# CM41x_M4 register map
Vendor: Analog Devices; Series: CM41x_M4; File version: 1p0
CPU: CM4 r0p1, little endian, MPU, FPU, 4 interrupt priority bits
Registers are 32-bit, read-write, reset 0x0 unless marked. A register's access mark holds for its fields unless they carry their own. Offsets are from the block's base; [hi:lo] are bit positions; lines under a group give offsets from that group; {n}, {i} and the like mark numbered series.

## TIMER0 — General-Purpose Timer Block
Base 0x41007000
Same registers: TIMER1 0x40021000
0x04 RUN
  [7:0] TMRnn range 0x00000000..0x000000FF — Start/Stop Timer n
0x08 RUN_SET
  [7:0] TMRnn range 0x00000000..0x000000FF — Start/Stop Timer n
0x0C RUN_CLR — Run Clear Register
  [7:0] TMRnn range 0x00000000..0x000000FF — Start/Stop Timer n
0x10 STOP_CFG — Stop Configuration Register
  [7:0] TMRnn range 0x00000000..0x000000FF — Stop Mode Select
0x14 STOP_CFG_SET — Stop Configuration Set Register
  [7:0] TMRnn range 0x00000000..0x000000FF — Stop Mode Select
0x18 STOP_CFG_CLR — Stop Configuration Clear Register
  [7:0] TMRnn range 0x00000000..0x000000FF — Stop Mode Select
0x1C DATA_IMSK reset 0xFF — Data Interrupt Mask Register
  [7:0] TMRnn range 0x00000000..0x000000FF — Data Interrupt Mask
0x20 STAT_IMSK reset 0xFF — Status Interrupt Mask Register
  [7:0] TMRnn range 0x00000000..0x000000FF — Status Interrupt Mask
0x24 TRG_MSK reset 0xFF — Trigger Master Mask Register
  [7:0] TMRnn range 0x00000000..0x000000FF — Trigger Output Mask
0x28 TRG_IE — Trigger Slave Enable Register
  [7:0] TMRnn range 0x00000000..0x000000FF — Trigger Input Enable
0x2C DATA_ILAT — Data Interrupt Latch Register
  [7:0] TMRnn range 0x00000000..0x000000FF — Data Interrupt Latch
0x30 STAT_ILAT — Status Interrupt Latch Register
  [7:0] TMRnn range 0x00000000..0x000000FF — Status Interrupt Latch
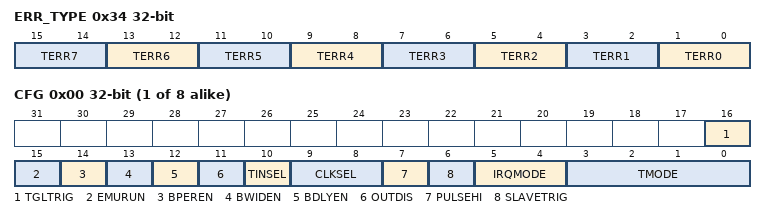
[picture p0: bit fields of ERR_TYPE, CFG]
0x34 ERR_TYPE — Error Type Status Register
  [2n+1:2n] TERR{n} ro (n=0..7) — Error Type for Timer {n}
    0=NO_ERR{n} (No Error); 1=CNTOVF{n} (Counter Overflow Error); 2=PERPRG{n} (PER Register Programming Error); 3=PULSEPRG{n} (WID or DLY Register Programming Error)
0x38 BCAST_PER — Broadcast Period Register
  [31:0] VALUE range 0x00000000..0xFFFFFFFF — Broadcast Period Value
0x3C BCAST_WID — Broadcast Width Register
  [31:0] VALUE range 0x00000000..0xFFFFFFFF — Broadcast Width Value
0x40 BCAST_DLY — Broadcast Delay Register
  [31:0] VALUE range 0x00000000..0xFFFFFFFF — Broadcast Delay Value
{0x60+0x20*i} TMR[{i}] (i=0..7) group — TMR block
  0x00 CFG — Timer n Configuration Register
    [16] TGLTRIG — Slave Trigger Toggle Enable
      0=Slave Trigger Response Depends on SLAVETRIG Bit Setting; 1=Slave Trigger Toggles Timer State
    [15] EMURUN — Emulation Run
      0=EMU_NOCNT (Stop Timer During Emulation); 1=EMU_CNT (Run Timer During Emulation)
    [14] BPEREN — Broadcast Period Enable
      0=BCASTPER_DIS (Disable Broadcast to PER Register); 1=BCASTPER_EN (Enable Broadcast to PER Register)
    [13] BWIDEN — Broadcast Width Enable
      0=BCASTWID_DIS (Disable Broadcast to WID Register); 1=BCASTWID_EN (Enable Broadcast to WID Register)
    [12] BDLYEN — Broadcast Delay Enable
      0=BCASTDLY_DIS (Disable Broadcast to DLY Register); 1=BCASTDLY_EN (Enable Broadcast to DLY Register)
    [11] OUTDIS — Output Disable
      0=PADOUT_EN (Enable TMR Pin Output Buffer); 1=PADOUT_DIS (Disable TMR Pin Output Buffer)
    [10] TINSEL — Timer Input Select (for WIDCAP, WATCHDOG, PININT modes)
      0=TINSEL_TMR (Use TMR Pin Input); 1=TINSEL_AUX (Use TMR Alternate Capture Input)
    [9:8] CLKSEL — Clock Select
      0=CLKSEL_SCLK (Use SCLK); 1=CLKSEL_ALT0 (Use TMR_ALT_CLK0 as TMR Clock); 3=CLKSEL_ALT1 (Use TMR_ALT_CLK1 as TMR Clock)
    [7] PULSEHI — Polarity Response Select
      0=NEG_EDGE (Negative Response or Pulse.); 1=POS_EDGE (Positive Response or Pulse.)
    [6] SLAVETRIG — Slave Trigger Response.
      0=TRIGSTOP (Pulse Stops Timer if it is Running); 1=TRIGSTART (Pulse Starts Timer if it is Stopped)
    [5:4] IRQMODE — Interrupt Modes
      0=Active Edge Mode; 1=Delay Expired Mode; 2=Width Plus Delay Expired Mode; 3=Period Expired Mode
    [3:0] TMODE — Timer Mode Select
      {v}=IDLE_MODE{v} (v=0..7); 8=WDPER_MODE (Period Watchdog Mode); 9=WDWID_MODE (Width Watchdog Mode); 10=WIDCAP0_MODE (Measurement Report at Asserting Edge of Waveform); 11=WIDCAP1_MODE (Measurement Report at Deasserting Edge of Waveform); 12=PWMCONT_MODE (Continuous PWMOUT Mode); 13=PWMSING_MODE (Single Pulse PWMOUT Mode); 14=EXTCLK_MODE; 15=PININT_MODE (PININT (pin interrupt) Mode)
  0x04 CNT reset 0x1 — Timer n Counter Register
    [31:0] VALUE ro — Counter Value
  0x08 PER — Timer n Period Register
    [31:0] VALUE range 0x00000000..0xFFFFFFFF — Period Value
  0x0C WID — Timer n Width Register
    [31:0] VALUE range 0x00000000..0xFFFFFFFF — Width Value
  0x10 DLY — Timer n Delay Register
    [31:0] VALUE range 0x00000000..0xFFFFFFFF — Delay Value
